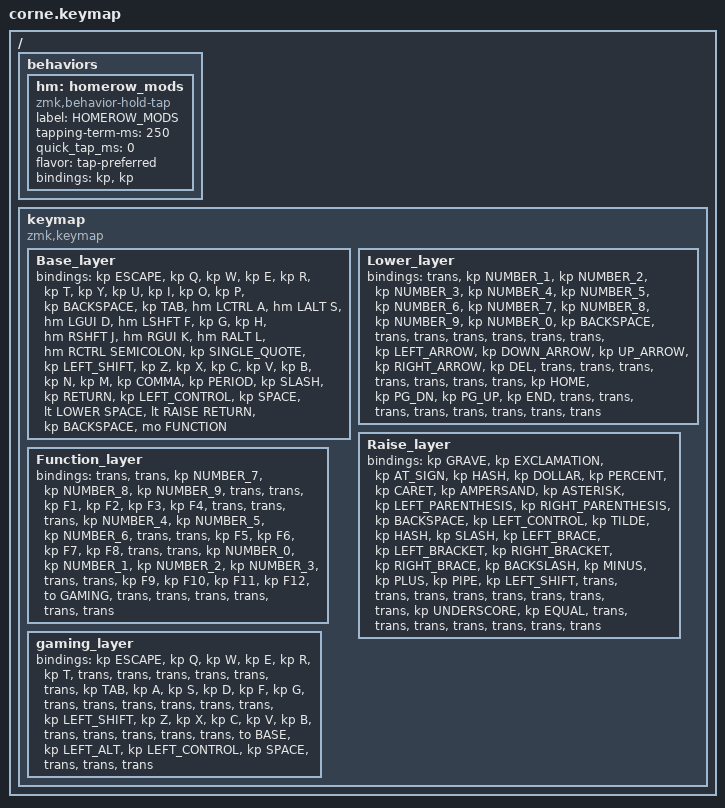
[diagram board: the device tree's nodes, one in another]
#include <behaviors.dtsi>
#include <dt-bindings/zmk/keys.h>

#define BASE 0
#define LOWER 1
#define RAISE 2
#define FUNCTION 3
#define GAMING 4

/ {
  behaviors {
    hm: homerow_mods {
      compatible = "zmk,behavior-hold-tap";
      label = "HOMEROW_MODS";
      #binding-cells = <2>;
      tapping-term-ms = <250>;
      quick_tap_ms = <0>;
      flavor = "tap-preferred";
      bindings = <&kp>, <&kp>;
    };
  };
  keymap {
    compatible = "zmk,keymap";

    Base_layer {
      bindings = <
        &kp ESCAPE &kp Q &kp W &kp E &kp R &kp T &kp Y &kp U &kp I &kp O &kp P &kp BACKSPACE &kp TAB &hm LCTRL A &hm LALT S &hm LGUI D &hm LSHFT F &kp G &kp H &hm RSHFT J &hm RGUI K &hm RALT L &hm RCTRL SEMICOLON &kp SINGLE_QUOTE &kp LEFT_SHIFT &kp Z &kp X &kp C &kp V &kp B &kp N &kp M &kp COMMA &kp PERIOD &kp SLASH &kp RETURN &kp LEFT_CONTROL &kp SPACE &lt LOWER SPACE &lt RAISE RETURN &kp BACKSPACE &mo FUNCTION 
      >;
    };

    Lower_layer {
      bindings = <
        &trans &kp NUMBER_1 &kp NUMBER_2 &kp NUMBER_3 &kp NUMBER_4 &kp NUMBER_5 &kp NUMBER_6 &kp NUMBER_7 &kp NUMBER_8 &kp NUMBER_9 &kp NUMBER_0 &kp BACKSPACE &trans &trans &trans &trans &trans &trans &kp LEFT_ARROW &kp DOWN_ARROW &kp UP_ARROW &kp RIGHT_ARROW &kp DEL &trans &trans &trans &trans &trans &trans &trans &kp HOME &kp PG_DN &kp PG_UP &kp END &trans &trans &trans &trans &trans &trans &trans &trans 
      >;
    };

    Raise_layer {
      bindings = <
        &kp GRAVE &kp EXCLAMATION &kp AT_SIGN &kp HASH &kp DOLLAR &kp PERCENT &kp CARET &kp AMPERSAND &kp ASTERISK &kp LEFT_PARENTHESIS &kp RIGHT_PARENTHESIS &kp BACKSPACE &kp LEFT_CONTROL &kp TILDE &kp HASH &kp SLASH &kp LEFT_BRACE &kp LEFT_BRACKET &kp RIGHT_BRACKET &kp RIGHT_BRACE &kp BACKSLASH &kp MINUS &kp PLUS &kp PIPE &kp LEFT_SHIFT &trans &trans &trans &trans &trans &trans &trans &trans &kp UNDERSCORE &kp EQUAL &trans &trans &trans &trans &trans &trans &trans 
      >;
    };

    Function_layer {
      bindings = <
        &trans &trans &kp NUMBER_7 &kp NUMBER_8 &kp NUMBER_9 &trans &trans &kp F1 &kp F2 &kp F3 &kp F4 &trans &trans &trans &kp NUMBER_4 &kp NUMBER_5 &kp NUMBER_6 &trans &trans &kp F5 &kp F6 &kp F7 &kp F8 &trans &trans &kp NUMBER_0 &kp NUMBER_1 &kp NUMBER_2 &kp NUMBER_3 &trans &trans &kp F9 &kp F10 &kp F11 &kp F12 &to GAMING &trans &trans &trans &trans &trans &trans 
      >;
    };

    gaming_layer {
      bindings = <
        &kp ESCAPE &kp Q &kp W &kp E &kp R &kp T &trans &trans &trans &trans &trans &trans &kp TAB &kp A &kp S &kp D &kp F &kp G &trans &trans &trans &trans &trans &trans &kp LEFT_SHIFT &kp Z &kp X &kp C &kp V &kp B &trans &trans &trans &trans &trans &to BASE &kp LEFT_ALT &kp LEFT_CONTROL &kp SPACE &trans &trans &trans 
      >;
    };

  };
};
